AUTOSAR XML (schema 00054)
package /SwComponentType/AdaptiveApplication
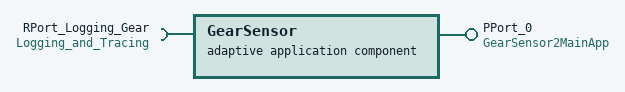
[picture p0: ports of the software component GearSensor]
  adaptive application sw component type GearSensor
    provide port PPort_0: provided-interface=GearSensor2MainApp
    require port RPort_Logging_Gear: required-interface=Logging_and_Tracing
    behavior InternalBehavior
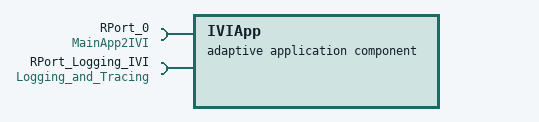
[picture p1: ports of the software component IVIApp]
  adaptive application sw component type IVIApp
    require port RPort_0: required-interface=MainApp2IVI
    require port RPort_Logging_IVI: required-interface=Logging_and_Tracing
    behavior InternalBehavior
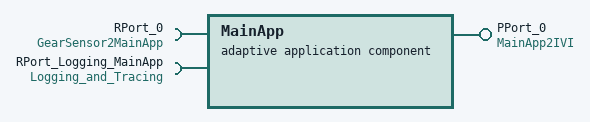
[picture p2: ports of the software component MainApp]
  adaptive application sw component type MainApp
    provide port PPort_0: provided-interface=MainApp2IVI
    require port RPort_0: required-interface=GearSensor2MainApp
    require port RPort_Logging_MainApp: required-interface=Logging_and_Tracing
    behavior InternalBehavior
package /SwComponentType/Composition
  composition sw component type HPC_0
    component MainApp: type=MainApp
    component GearSensor: type=GearSensor
    component IVI: type=IVIApp
    connect GearSensor.PPort_0 -> MainApp.RPort_0
    connect MainApp.PPort_0 -> IVI.RPort_0
  composition sw component type System  # Root SW Composition
    component HPC_0: type=HPC_0
package /Executable/GearSensor
  executable GearSensor: category=APPLICATION_LEVEL, reporting-behavior=REPORTS-EXECUTION-STATE, version=1.0.0
    root sw component prototype AA: application-type=GearSensor
package /Executable/GearSensor/Manifest
  dlt log sink to port prototype mapping GearSensor_AA_RPort_Logging_Gear: r-port-prototype=AA.RPort_Logging_Gear
package /Executable/IVI
  executable IVI: category=APPLICATION_LEVEL, reporting-behavior=REPORTS-EXECUTION-STATE, version=1.0.0
    root sw component prototype AA: application-type=IVIApp
package /Executable/IVI/Manifest
  dlt log sink to port prototype mapping IVI_AA_RPort_Logging_IVI: r-port-prototype=AA.RPort_Logging_IVI
package /Executable/MainApp
  executable MainApp: category=APPLICATION_LEVEL, reporting-behavior=REPORTS-EXECUTION-STATE, version=1.0.0
    root sw component prototype AA: application-type=MainApp
package /Executable/MainApp/Manifest
  dlt log sink to port prototype mapping MainApp_AA_RPort_Logging_MainApp: r-port-prototype=AA.RPort_Logging_MainApp
